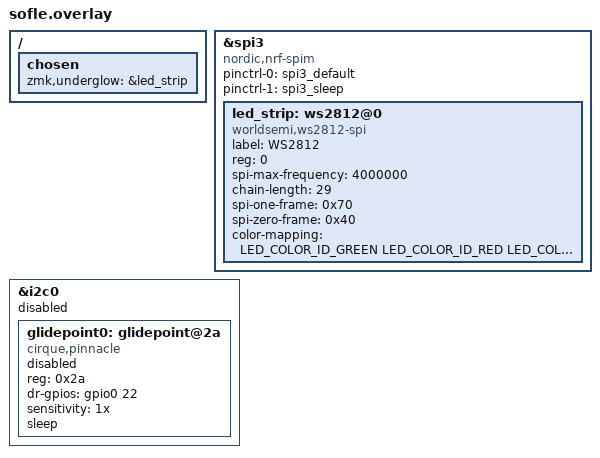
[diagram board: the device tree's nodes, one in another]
#include <dt-bindings/led/led.h>

&spi3 {
  compatible = "nordic,nrf-spim";
  status = "okay";
  pinctrl-0 = <&spi3_default>;
  pinctrl-1 = <&spi3_sleep>;
  pinctrl-names = "default", "sleep";
  led_strip: ws2812@0 {
    compatible = "worldsemi,ws2812-spi";
    label = "WS2812";
    /* SPI */
    reg = <0>; /* ignored, but necessary for SPI bindings */
    spi-max-frequency = <4000000>;
    /* WS2812 */
    chain-length = <29>; /* number of LEDs */
    spi-one-frame = <0x70>;
    spi-zero-frame = <0x40>;
    color-mapping = <LED_COLOR_ID_GREEN
                          LED_COLOR_ID_RED
                          LED_COLOR_ID_BLUE>;
  };
};

/ {
    chosen {
        zmk,underglow = &led_strip;
    };
};

&i2c0 {
    status = "disabled";
    glidepoint0: glidepoint@2a {
        compatible = "cirque,pinnacle";
        reg = <0x2a>;
        status = "disabled";
        dr-gpios = <&gpio0 22 (GPIO_ACTIVE_HIGH)>;

        sensitivity = "1x";
        sleep;
        // no-taps;
    };

};
